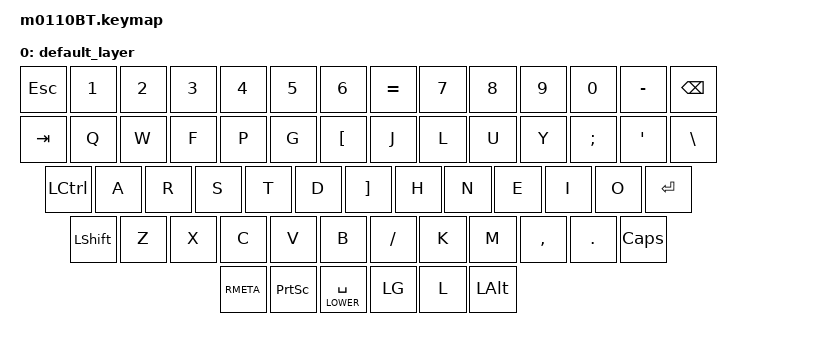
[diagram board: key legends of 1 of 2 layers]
/*
 * Copyright (c) 2020 The ZMK Contributors
 *
 * SPDX-License-Identifier: MIT
 */

#include <behaviors.dtsi>
#include <dt-bindings/zmk/keys.h>
#include <dt-bindings/zmk/bt.h>
#include <dt-bindings/zmk/outputs.h>


#define DEFAULT 0
#define LOWER   1



/ {
	keymap {
		compatible = "zmk,keymap";

		default_layer {
			bindings = <
																																               
			&kp ESC   &kp N1    &kp N2   &kp N3    &kp N4    &kp N5    &kp N6    &kp EQUAL  &kp N7    &kp N8    &kp N9   &kp N0    &kp MINUS &kp BSPC 
			&kp TAB   &kp Q  &kp W &kp F    &kp P  &kp G  		&kp LBKT	 &kp J    &kp L    &kp U    &kp Y    &kp SEMI  &kp SQT  &kp BSLH
			&kp LCTRL   &kp A     &kp R   &kp S    &kp T    &kp D     &kp RBKT     &kp H     &kp N    &kp E      &kp I     &kp O    &kp ENTER 	
			&kp LSHFT   &kp Z    &kp X    &kp C     &kp V     &kp B     &kp FSLH     &kp K      &kp M     &kp COMMA     &kp DOT    &kp CAPS
									 &kp RMETA	 &kp PSCRN  &lt LOWER SPACE   &kp LG (L) &kp LALT
	
			>;
		};

		lower_layer {
			bindings = <
																																               
			&reset  &kp F1   &kp F2   &kp F3    &kp F4    &kp F5    &kp F6    &kp F12  &kp F7    &kp F8    &kp F9   &kp F10    &kp F11 &kp DEL
			&trans  	 &trans  &kp UP 	 &trans  	&trans  &trans		&trans	 &trans    				&kp LG(RC(D))    &kp U    &kp Y    &trans &trans  &trans
			&trans   &kp LEFT     &kp DOWN  &kp RIGHT   &trans   &trans     &trans   &kp LG(RC(LEFT))     &kp LG(RC(RIGHT))    &trans      &trans    &trans   &kp LG(TAB)	
			&trans   &trans   &trans    &trans   &trans    &trans   &trans     &trans      &kp LG(RC(F4))     &trans    &trans     &trans 
									 &bt BT_PRV  &bt BT_CLR &trans     &out OUT_TOG &bt BT_NXT
			>;
		};
	};
};
